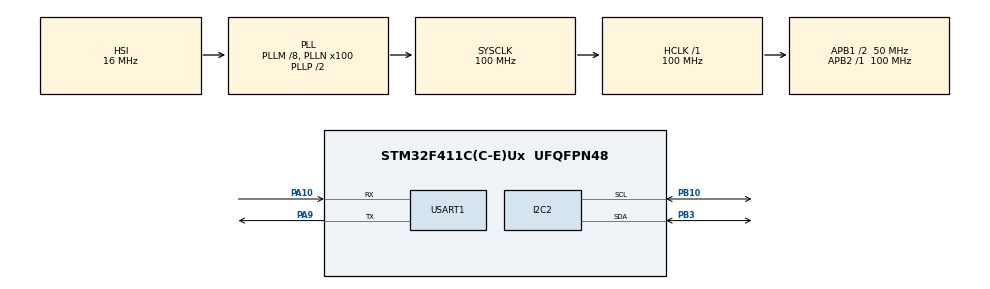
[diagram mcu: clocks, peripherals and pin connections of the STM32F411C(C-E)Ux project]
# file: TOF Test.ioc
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Mcu.Family=STM32F4
Mcu.Name=STM32F411C(C-E)Ux
Mcu.Package=UFQFPN48
NVIC.PriorityGroup=NVIC_PRIORITYGROUP_4
PA10.Mode=Asynchronous
PA10.Signal=USART1_RX
PA13.Mode=Serial_Wire
PA13.Signal=SYS_JTMS-SWDIO
PA14.Mode=Serial_Wire
PA14.Signal=SYS_JTCK-SWCLK
PA9.Mode=Asynchronous
PA9.Signal=USART1_TX
PB10.Mode=I2C
PB10.Signal=I2C2_SCL
PB3.Mode=I2C
PB3.Signal=I2C2_SDA
PH0\ -\ OSC_IN.Mode=HSE-External-Oscillator
PH0\ -\ OSC_IN.Signal=RCC_OSC_IN
PH1\ -\ OSC_OUT.Mode=HSE-External-Oscillator
PH1\ -\ OSC_OUT.Signal=RCC_OSC_OUT
ProjectManager.HeapSize=0x200
ProjectManager.StackSize=0x400
ProjectManager.TargetToolchain=STM32CubeIDE
RCC.48MHZClocksFreq_Value=50000000
RCC.AHBFreq_Value=100000000
RCC.APB1CLKDivider=RCC_HCLK_DIV2
RCC.APB1Freq_Value=50000000
RCC.APB1TimFreq_Value=100000000
RCC.APB2Freq_Value=100000000
RCC.APB2TimFreq_Value=100000000
RCC.CortexFreq_Value=100000000
RCC.HCLKFreq_Value=100000000
RCC.HSE_VALUE=25000000
RCC.HSI_VALUE=16000000
RCC.LSE_VALUE=32768
RCC.PLLM=8
RCC.PLLN=100
RCC.SYSCLKFreq_VALUE=100000000
RCC.SYSCLKSource=RCC_SYSCLKSOURCE_PLLCLK
RCC.VCOOutputFreq_Value=200000000
USART1.VirtualMode=VM_ASYNC
board=custom

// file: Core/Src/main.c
/* USER CODE BEGIN Header */
/**
  ******************************************************************************
  * @file           : main.c
  * @brief          : Main program body
  ******************************************************************************
  * @attention
  *
  * Copyright (c) 2022 STMicroelectronics.
  * All rights reserved.
  *
  * This software is licensed under terms that can be found in the LICENSE file
  * in the root directory of this software component.
  * If no LICENSE file comes with this software, it is provided AS-IS.
  *
  ******************************************************************************
  */
/* USER CODE END Header */
#include "main.h"
#include "string.h"
#include "stdio.h"
#include "lidar.h"
#include "vl53l0x_api.h"

 I2C_HandleTypeDef hi2c2;

UART_HandleTypeDef huart1;

VL53L0X_Dev_t lidar1_dev;
VL53L0X_DEV lidar1 = &lidar1_dev;

void SystemClock_Config(void);
static void MX_GPIO_Init(void);
static void MX_I2C2_Init(void);
static void MX_USART1_UART_Init(void);

int main(void)
{
  /* USER CODE BEGIN 1 */
	uint8_t mdr1;
	VL53L0X_RangingMeasurementData_t range_data1;
	uint8_t buff[24] = {0};
	HAL_StatusTypeDef ret;
	uint16_t tof_data = {0};
  /* USER CODE END 1 */

  /* MCU Configuration--------------------------------------------------------*/

  /* Reset of all peripherals, Initializes the Flash interface and the Systick. */
  HAL_Init();

  /* Configure the system clock */
  SystemClock_Config();

  /* Initialize all configured peripherals */
  MX_GPIO_Init();
  MX_I2C2_Init();
  MX_USART1_UART_Init();
  /* USER CODE BEGIN 2 */

  init_lidar(lidar1, &hi2c2);
  check_ref_reg(lidar1, &huart1);

  VL53L0X_Error Status = VL53L0X_ERROR_NONE;
  if (Status == VL53L0X_ERROR_NONE)
	  Status = setup_lidar_continuous(lidar1);

  /* USER CODE END 2 */

  /* Infinite loop */
  while (1)
  {

	  if (Status == VL53L0X_ERROR_NONE)
	  {
		  Status = VL53L0X_GetMeasurementDataReady(lidar1, &mdr1);
	  }

	  if (mdr1 && Status == VL53L0X_ERROR_NONE)
	  {
		  Status = VL53L0X_GetRangingMeasurementData(lidar1, &range_data1);
		  tof_data = range_data1.RangeMilliMeter;
		  VL53L0X_ClearInterruptMask(lidar1, VL53L0X_REG_SYSTEM_INTERRUPT_GPIO_NEW_SAMPLE_READY);
	  }
    /* USER CODE BEGIN 3 */
	  sprintf((char*)buff, "TOF Distance: %d\n\r", tof_data);
	  ret = HAL_UART_Transmit(&huart1, buff, strlen((char*)buff), HAL_MAX_DELAY);
	  HAL_Delay(100);
  }
  /* USER CODE END 3 */
}

void SystemClock_Config(void)
{
  RCC_OscInitTypeDef RCC_OscInitStruct = {0};
  RCC_ClkInitTypeDef RCC_ClkInitStruct = {0};

  /** Configure the main internal regulator output voltage
  */
  __HAL_RCC_PWR_CLK_ENABLE();
  __HAL_PWR_VOLTAGESCALING_CONFIG(PWR_REGULATOR_VOLTAGE_SCALE1);

  /** Initializes the RCC Oscillators according to the specified parameters
  * in the RCC_OscInitTypeDef structure.
  */
  RCC_OscInitStruct.OscillatorType = RCC_OSCILLATORTYPE_HSI;
  RCC_OscInitStruct.HSIState = RCC_HSI_ON;
  RCC_OscInitStruct.HSICalibrationValue = RCC_HSICALIBRATION_DEFAULT;
  RCC_OscInitStruct.PLL.PLLState = RCC_PLL_ON;
  RCC_OscInitStruct.PLL.PLLSource = RCC_PLLSOURCE_HSI;
  RCC_OscInitStruct.PLL.PLLM = 8;
  RCC_OscInitStruct.PLL.PLLN = 100;
  RCC_OscInitStruct.PLL.PLLP = RCC_PLLP_DIV2;
  RCC_OscInitStruct.PLL.PLLQ = 4;
  if (HAL_RCC_OscConfig(&RCC_OscInitStruct) != HAL_OK)
  {
    Error_Handler();
  }

  /** Initializes the CPU, AHB and APB buses clocks
  */
  RCC_ClkInitStruct.ClockType = RCC_CLOCKTYPE_HCLK|RCC_CLOCKTYPE_SYSCLK
                              |RCC_CLOCKTYPE_PCLK1|RCC_CLOCKTYPE_PCLK2;
  RCC_ClkInitStruct.SYSCLKSource = RCC_SYSCLKSOURCE_PLLCLK;
  RCC_ClkInitStruct.AHBCLKDivider = RCC_SYSCLK_DIV1;
  RCC_ClkInitStruct.APB1CLKDivider = RCC_HCLK_DIV2;
  RCC_ClkInitStruct.APB2CLKDivider = RCC_HCLK_DIV1;

  if (HAL_RCC_ClockConfig(&RCC_ClkInitStruct, FLASH_LATENCY_3) != HAL_OK)
  {
    Error_Handler();
  }
}

static void MX_I2C2_Init(void)
{

  hi2c2.Instance = I2C2;
  hi2c2.Init.ClockSpeed = 100000;
  hi2c2.Init.DutyCycle = I2C_DUTYCYCLE_2;
  hi2c2.Init.OwnAddress1 = 0;
  hi2c2.Init.AddressingMode = I2C_ADDRESSINGMODE_7BIT;
  hi2c2.Init.DualAddressMode = I2C_DUALADDRESS_DISABLE;
  hi2c2.Init.OwnAddress2 = 0;
  hi2c2.Init.GeneralCallMode = I2C_GENERALCALL_DISABLE;
  hi2c2.Init.NoStretchMode = I2C_NOSTRETCH_DISABLE;
  if (HAL_I2C_Init(&hi2c2) != HAL_OK)
  {
    Error_Handler();
  }

}

static void MX_USART1_UART_Init(void)
{

  huart1.Instance = USART1;
  huart1.Init.BaudRate = 115200;
  huart1.Init.WordLength = UART_WORDLENGTH_8B;
  huart1.Init.StopBits = UART_STOPBITS_1;
  huart1.Init.Parity = UART_PARITY_NONE;
  huart1.Init.Mode = UART_MODE_TX_RX;
  huart1.Init.HwFlowCtl = UART_HWCONTROL_NONE;
  huart1.Init.OverSampling = UART_OVERSAMPLING_16;
  if (HAL_UART_Init(&huart1) != HAL_OK)
  {
    Error_Handler();
  }

}

static void MX_GPIO_Init(void)
{

  /* GPIO Ports Clock Enable */
  __HAL_RCC_GPIOH_CLK_ENABLE();
  __HAL_RCC_GPIOB_CLK_ENABLE();
  __HAL_RCC_GPIOA_CLK_ENABLE();

}

void Error_Handler(void)
{
  __disable_irq();
  while (1)
  {
  }
}
